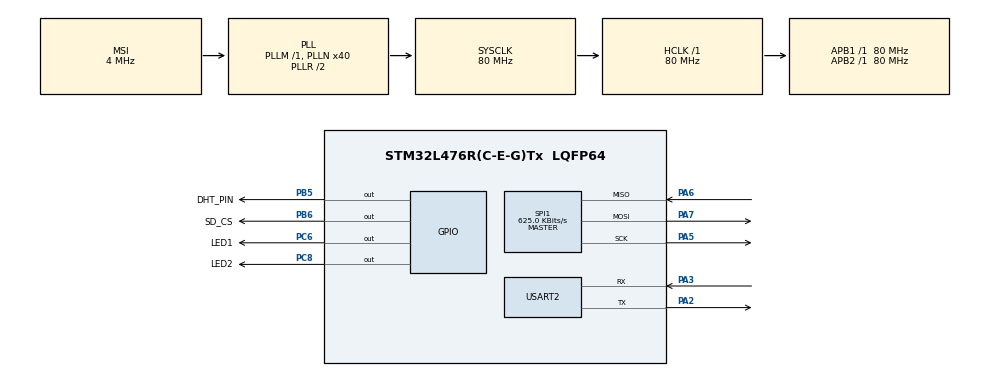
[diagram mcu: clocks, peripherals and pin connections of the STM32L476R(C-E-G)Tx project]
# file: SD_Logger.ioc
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FATFS._FS_NORTC=1
FREERTOS.Tasks01=defaultTask,24,128,StartDefaultTask,Default,NULL,Dynamic,NULL,NULL
FREERTOS.configTOTAL_HEAP_SIZE=20480
Mcu.Family=STM32L4
Mcu.Name=STM32L476R(C-E-G)Tx
Mcu.Package=LQFP64
NVIC.PriorityGroup=NVIC_PRIORITYGROUP_4
NVIC.TIM6_DAC_IRQn=true\:15\:0\:false\:false\:true\:false\:false\:true\:true
NVIC.TimeBase=TIM6_DAC_IRQn
NVIC.TimeBaseIP=TIM6
PA13\ (JTMS-SWDIO).Mode=Serial_Wire
PA13\ (JTMS-SWDIO).Signal=SYS_JTMS-SWDIO
PA14\ (JTCK-SWCLK).Mode=Serial_Wire
PA14\ (JTCK-SWCLK).Signal=SYS_JTCK-SWCLK
PA2.Mode=Asynchronous
PA2.Signal=USART2_TX
PA3.Mode=Asynchronous
PA3.Signal=USART2_RX
PA5.Mode=Full_Duplex_Master
PA5.Signal=SPI1_SCK
PA6.GPIO_PuPd=GPIO_PULLUP
PA6.Mode=Full_Duplex_Master
PA6.Signal=SPI1_MISO
PA7.Mode=Full_Duplex_Master
PA7.Signal=SPI1_MOSI
PB5.GPIO_Label=DHT_PIN
PB5.Signal=GPIO_Output
PB6.GPIO_Label=SD_CS
PB6.PinState=GPIO_PIN_SET
PB6.Signal=GPIO_Output
PC6.GPIO_Label=LED1
PC6.Signal=GPIO_Output
PC8.GPIO_Label=LED2
PC8.Signal=GPIO_Output
PH0-OSC_IN\ (PH0).Mode=HSE-External-Clock-Source
PH0-OSC_IN\ (PH0).Signal=RCC_OSC_IN
ProjectManager.HeapSize=0x200
ProjectManager.StackSize=0x400
ProjectManager.TargetToolchain=CMake
RCC.ADCFreq_Value=16000000
RCC.AHBFreq_Value=80000000
RCC.APB1Freq_Value=80000000
RCC.APB1TimFreq_Value=80000000
RCC.APB2Freq_Value=80000000
RCC.APB2TimFreq_Value=80000000
RCC.CortexFreq_Value=80000000
RCC.HCLKFreq_Value=80000000
RCC.HSE_VALUE=8000000
RCC.HSI_VALUE=16000000
RCC.LSE_VALUE=32768
RCC.MSI_VALUE=4000000
RCC.PLLN=40
RCC.SYSCLKFreq_VALUE=80000000
RCC.SYSCLKSource=RCC_SYSCLKSOURCE_PLLCLK
RCC.USBFreq_Value=16000000
RCC.VCOOutputFreq_Value=160000000
SPI1.BaudRatePrescaler=SPI_BAUDRATEPRESCALER_128
SPI1.CalculateBaudRate=625.0 KBits/s
SPI1.DataSize=SPI_DATASIZE_8BIT
SPI1.Direction=SPI_DIRECTION_2LINES
SPI1.Mode=SPI_MODE_MASTER
SPI1.VirtualType=VM_MASTER
USART2.VirtualMode-Asynchronous=VM_ASYNC
VP_FATFS_VS_Generic.Mode=User_defined
VP_FREERTOS_VS_CMSIS_V2.Mode=CMSIS_V2
VP_SYS_VS_tim6.Mode=TIM6
board=custom

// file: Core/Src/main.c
/* USER CODE BEGIN Header */
/**
 ******************************************************************************
 * @file           : main.c
 * @brief          : Main program body
 ******************************************************************************
 * @attention
 *
 * Copyright (c) 2026 STMicroelectronics.
 * All rights reserved.
 *
 * This software is licensed under terms that can be found in the LICENSE file
 * in the root directory of this software component.
 * If no LICENSE file comes with this software, it is provided AS-IS.
 *
 ******************************************************************************
 */
/* USER CODE END Header */
#include "main.h"
#include "cmsis_os.h"
#include "fatfs.h"

/* USER CODE BEGIN Includes */
#include "logger_app.h"

/* USER CODE END Includes */

SPI_HandleTypeDef hspi1;

UART_HandleTypeDef huart2;

/* Definitions for defaultTask */
osThreadId_t defaultTaskHandle;
const osThreadAttr_t defaultTask_attributes = {
    .name = "defaultTask",
    .stack_size = 128 * 4,
    .priority = (osPriority_t)osPriorityNormal,
};

void SystemClock_Config(void);
static void MX_GPIO_Init(void);
static void MX_SPI1_Init(void);
static void MX_USART2_UART_Init(void);
void StartDefaultTask(void *argument);

int main(void)
{

    /* MCU
     * Configuration--------------------------------------------------------*/

    /* Reset of all peripherals, Initializes the Flash interface and the
     * Systick. */
    HAL_Init();

    /* Configure the system clock */
    SystemClock_Config();

    /* Initialize all configured peripherals */
    MX_GPIO_Init();
    MX_SPI1_Init();
    MX_USART2_UART_Init();
    MX_FATFS_Init();

    /* Init scheduler */
    osKernelInitialize();

    /* Create the thread(s) */
    /* creation of defaultTask */
    defaultTaskHandle =
        osThreadNew(StartDefaultTask, NULL, &defaultTask_attributes);

    /* USER CODE BEGIN RTOS_THREADS */
    LoggerApp_Init();
    /* USER CODE END RTOS_THREADS */

    /* Start scheduler */
    osKernelStart();

    /* We should never get here as control is now taken by the scheduler */

    /* Infinite loop */
    while (1)
    {

    }
}

void SystemClock_Config(void)
{
    RCC_OscInitTypeDef RCC_OscInitStruct = {0};
    RCC_ClkInitTypeDef RCC_ClkInitStruct = {0};

    /** Configure the main internal regulator output voltage
     */
    if (HAL_PWREx_ControlVoltageScaling(PWR_REGULATOR_VOLTAGE_SCALE1) != HAL_OK)
    {
        Error_Handler();
    }

    /** Initializes the RCC Oscillators according to the specified parameters
     * in the RCC_OscInitTypeDef structure.
     */
    RCC_OscInitStruct.OscillatorType = RCC_OSCILLATORTYPE_MSI;
    RCC_OscInitStruct.MSIState = RCC_MSI_ON;
    RCC_OscInitStruct.MSICalibrationValue = 0;
    RCC_OscInitStruct.MSIClockRange = RCC_MSIRANGE_6;
    RCC_OscInitStruct.PLL.PLLState = RCC_PLL_ON;
    RCC_OscInitStruct.PLL.PLLSource = RCC_PLLSOURCE_MSI;
    RCC_OscInitStruct.PLL.PLLM = 1;
    RCC_OscInitStruct.PLL.PLLN = 40;
    RCC_OscInitStruct.PLL.PLLP = RCC_PLLP_DIV7;
    RCC_OscInitStruct.PLL.PLLQ = RCC_PLLQ_DIV2;
    RCC_OscInitStruct.PLL.PLLR = RCC_PLLR_DIV2;
    if (HAL_RCC_OscConfig(&RCC_OscInitStruct) != HAL_OK)
    {
        Error_Handler();
    }

    /** Initializes the CPU, AHB and APB buses clocks
     */
    RCC_ClkInitStruct.ClockType = RCC_CLOCKTYPE_HCLK | RCC_CLOCKTYPE_SYSCLK |
                                  RCC_CLOCKTYPE_PCLK1 | RCC_CLOCKTYPE_PCLK2;
    RCC_ClkInitStruct.SYSCLKSource = RCC_SYSCLKSOURCE_PLLCLK;
    RCC_ClkInitStruct.AHBCLKDivider = RCC_SYSCLK_DIV1;
    RCC_ClkInitStruct.APB1CLKDivider = RCC_HCLK_DIV1;
    RCC_ClkInitStruct.APB2CLKDivider = RCC_HCLK_DIV1;

    if (HAL_RCC_ClockConfig(&RCC_ClkInitStruct, FLASH_LATENCY_4) != HAL_OK)
    {
        Error_Handler();
    }
}

static void MX_SPI1_Init(void)
{

    /* SPI1 parameter configuration*/
    hspi1.Instance = SPI1;
    hspi1.Init.Mode = SPI_MODE_MASTER;
    hspi1.Init.Direction = SPI_DIRECTION_2LINES;
    hspi1.Init.DataSize = SPI_DATASIZE_8BIT;
    hspi1.Init.CLKPolarity = SPI_POLARITY_LOW;
    hspi1.Init.CLKPhase = SPI_PHASE_1EDGE;
    hspi1.Init.NSS = SPI_NSS_SOFT;
    hspi1.Init.BaudRatePrescaler = SPI_BAUDRATEPRESCALER_128;
    hspi1.Init.FirstBit = SPI_FIRSTBIT_MSB;
    hspi1.Init.TIMode = SPI_TIMODE_DISABLE;
    hspi1.Init.CRCCalculation = SPI_CRCCALCULATION_DISABLE;
    hspi1.Init.CRCPolynomial = 7;
    hspi1.Init.CRCLength = SPI_CRC_LENGTH_DATASIZE;
    hspi1.Init.NSSPMode = SPI_NSS_PULSE_ENABLE;
    if (HAL_SPI_Init(&hspi1) != HAL_OK)
    {
        Error_Handler();
    }
}

static void MX_USART2_UART_Init(void)
{

    huart2.Instance = USART2;
    huart2.Init.BaudRate = 115200;
    huart2.Init.WordLength = UART_WORDLENGTH_8B;
    huart2.Init.StopBits = UART_STOPBITS_1;
    huart2.Init.Parity = UART_PARITY_NONE;
    huart2.Init.Mode = UART_MODE_TX_RX;
    huart2.Init.HwFlowCtl = UART_HWCONTROL_NONE;
    huart2.Init.OverSampling = UART_OVERSAMPLING_16;
    huart2.Init.OneBitSampling = UART_ONE_BIT_SAMPLE_DISABLE;
    huart2.AdvancedInit.AdvFeatureInit = UART_ADVFEATURE_NO_INIT;
    if (HAL_UART_Init(&huart2) != HAL_OK)
    {
        Error_Handler();
    }
}

static void MX_GPIO_Init(void)
{
    GPIO_InitTypeDef GPIO_InitStruct = {0};

    /* GPIO Ports Clock Enable */
    __HAL_RCC_GPIOH_CLK_ENABLE();
    __HAL_RCC_GPIOA_CLK_ENABLE();
    __HAL_RCC_GPIOC_CLK_ENABLE();
    __HAL_RCC_GPIOB_CLK_ENABLE();

    /*Configure GPIO pin Output Level */
    HAL_GPIO_WritePin(GPIOC, LED1_Pin | LED2_Pin, GPIO_PIN_RESET);

    /*Configure GPIO pin Output Level */
    HAL_GPIO_WritePin(DHT_PIN_GPIO_Port, DHT_PIN_Pin, GPIO_PIN_RESET);

    /*Configure GPIO pin Output Level */
    HAL_GPIO_WritePin(SD_CS_GPIO_Port, SD_CS_Pin, GPIO_PIN_SET);

    /*Configure GPIO pins : LED1_Pin LED2_Pin */
    GPIO_InitStruct.Pin = LED1_Pin | LED2_Pin;
    GPIO_InitStruct.Mode = GPIO_MODE_OUTPUT_PP;
    GPIO_InitStruct.Pull = GPIO_NOPULL;
    GPIO_InitStruct.Speed = GPIO_SPEED_FREQ_LOW;
    HAL_GPIO_Init(GPIOC, &GPIO_InitStruct);

    /*Configure GPIO pins : DHT_PIN_Pin SD_CS_Pin */
    GPIO_InitStruct.Pin = DHT_PIN_Pin | SD_CS_Pin;
    GPIO_InitStruct.Mode = GPIO_MODE_OUTPUT_PP;
    GPIO_InitStruct.Pull = GPIO_NOPULL;
    GPIO_InitStruct.Speed = GPIO_SPEED_FREQ_LOW;
    HAL_GPIO_Init(GPIOB, &GPIO_InitStruct);

}

void StartDefaultTask(void *argument)
{
    for (;;)
    {
        osDelay(1);
    }
}

void HAL_TIM_PeriodElapsedCallback(TIM_HandleTypeDef *htim)
{
    if (htim->Instance == TIM6)
    {
        HAL_IncTick();
    }
}

void Error_Handler(void)
{
    /* USER CODE BEGIN Error_Handler_Debug */
    /* User can add his own implementation to report the HAL error return state
     */
    __disable_irq();
    while (1)
    {
    }
    /* USER CODE END Error_Handler_Debug */
}
#ifdef USE_FULL_ASSERT
/**
 * @brief  Reports the name of the source file and the source line number
 *         where the assert_param error has occurred.
 * @param  file: pointer to the source file name
 * @param  line: assert_param error line source number
 * @retval None
 */
void assert_failed(uint8_t *file, uint32_t line)
{
    /* USER CODE BEGIN 6 */
    /* User can add his own implementation to report the file name and line
       number, ex: printf("Wrong parameters value: file %s on line %d\r\n",
       file, line) */
    /* USER CODE END 6 */
}
#endif /* USE_FULL_ASSERT */
